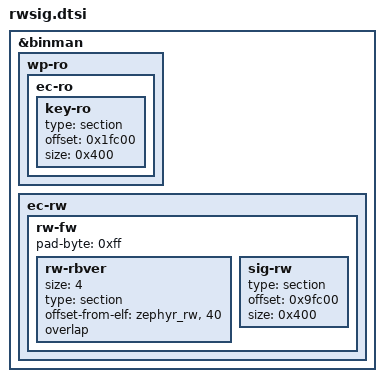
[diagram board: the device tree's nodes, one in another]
/* Copyright 2023 The ChromiumOS Authors.
 * Use of this source code is governed by a BSD-style license that can be
 * found in the LICENSE file.
 */

&binman {
	wp-ro {
		ec-ro {
			key-ro {
				type = "section";
				offset = <0x1fc00>;
				size = <0x400>;
			};
		};
	};

	ec-rw {
		rw-fw {
			rw-rbver {
				size = <4>;
				type = "section";
				/* points to
				 * current_image_data.rollback_version
				 */
				offset-from-elf = <&zephyr_rw>,
					"current_image_data", <40>;
				overlap;
			};

			sig-rw {
				type = "section";
				offset = <0x9fc00>;
				size = <0x400>;
			};
			pad-byte = <0xff>;
		};
	};
};
